AUTOSAR XML (schema 00046)
package /ComponentTypes
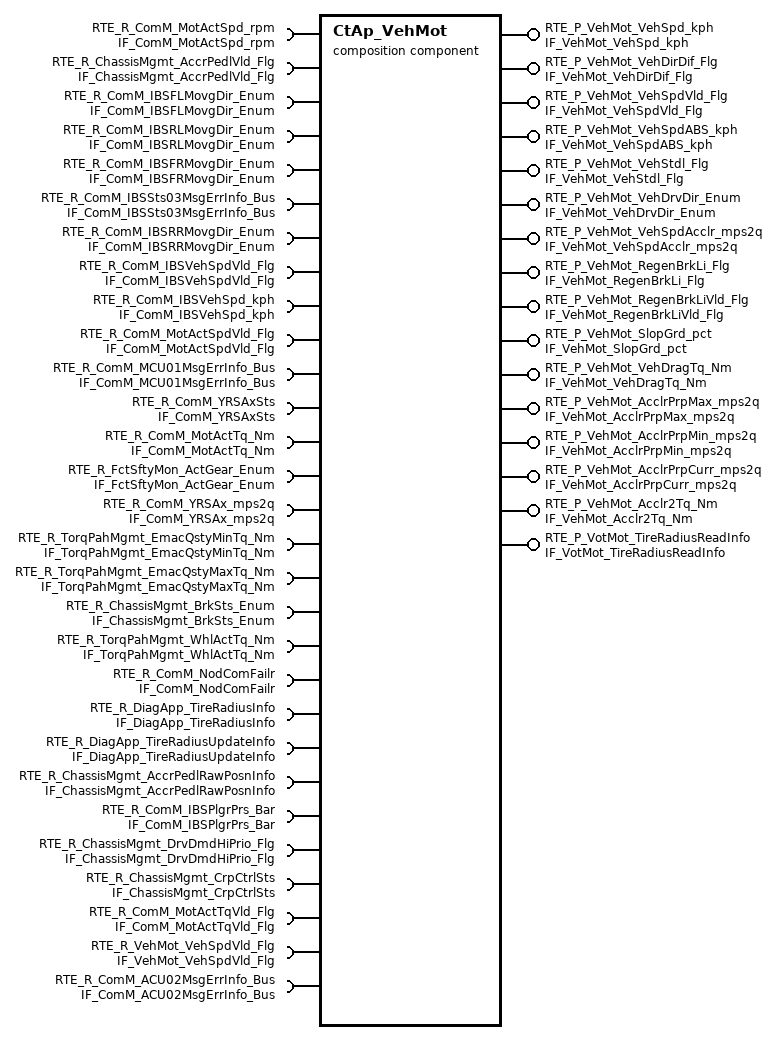
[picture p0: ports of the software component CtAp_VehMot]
  composition sw component type CtAp_VehMot
    require port RTE_R_ComM_MotActSpd_rpm: nonqueued-receiver-com-spec{data-element=tec_ComM_MotActSpd_rpm, filter=data-filter-type=ALWAYS, init-value=0}, required-interface=IF_ComM_MotActSpd_rpm
    15 x provide port:
      RTE_P_VehMot_VehSpd_kph: nonqueued-sender-com-spec{data-element=tec_VehMot_VehSpd_kph, init-value=0}, provided-interface=IF_VehMot_VehSpd_kph
      RTE_P_VehMot_VehDirDif_Flg: nonqueued-sender-com-spec{data-element=tec_VehMot_VehDirDif_Flg, init-value=0}, provided-interface=IF_VehMot_VehDirDif_Flg
      RTE_P_VehMot_VehSpdVld_Flg: nonqueued-sender-com-spec{data-element=tec_VehMot_VehSpdVld_Flg, init-value=0}, provided-interface=IF_VehMot_VehSpdVld_Flg
      RTE_P_VehMot_VehSpdABS_kph: nonqueued-sender-com-spec{data-element=tec_VehMot_VehSpdABS_kph, init-value=0}, provided-interface=IF_VehMot_VehSpdABS_kph
      RTE_P_VehMot_VehStdl_Flg: nonqueued-sender-com-spec{data-element=tec_VehMot_VehStdl_Flg, init-value=0}, provided-interface=IF_VehMot_VehStdl_Flg
      RTE_P_VehMot_VehDrvDir_Enum: nonqueued-sender-com-spec{data-element=tec_VehMot_VehDrvDir_Enum, init-value=0}, provided-interface=IF_VehMot_VehDrvDir_Enum
      RTE_P_VehMot_VehSpdAcclr_mps2q: nonqueued-sender-com-spec{data-element=tec_VehMot_VehSpdAcclr_mps2q, init-value=0}, provided-interface=IF_VehMot_VehSpdAcclr_mps2q
      RTE_P_VehMot_RegenBrkLi_Flg: nonqueued-sender-com-spec{data-element=tec_VehMot_RegenBrkLi_Flg, init-value=0}, provided-interface=IF_VehMot_RegenBrkLi_Flg
      RTE_P_VehMot_RegenBrkLiVld_Flg: nonqueued-sender-com-spec{data-element=tec_VehMot_RegenBrkLiVld_Flg, init-value=0}, provided-interface=IF_VehMot_RegenBrkLiVld_Flg
      RTE_P_VehMot_SlopGrd_pct: nonqueued-sender-com-spec{data-element=tec_VehMot_SlopGrd_pct, init-value=0}, provided-interface=IF_VehMot_SlopGrd_pct
      RTE_P_VehMot_VehDragTq_Nm: nonqueued-sender-com-spec{data-element=tec_VehMot_VehDragTq_Nm, init-value=0}, provided-interface=IF_VehMot_VehDragTq_Nm
      RTE_P_VehMot_AcclrPrpMax_mps2q: nonqueued-sender-com-spec{data-element=tec_VehMot_AcclrPrpMax_mps2q, init-value=0}, provided-interface=IF_VehMot_AcclrPrpMax_mps2q
      RTE_P_VehMot_AcclrPrpMin_mps2q: nonqueued-sender-com-spec{data-element=tec_VehMot_AcclrPrpMin_mps2q, init-value=0}, provided-interface=IF_VehMot_AcclrPrpMin_mps2q
      RTE_P_VehMot_AcclrPrpCurr_mps2q: nonqueued-sender-com-spec{data-element=tec_VehMot_AcclrPrpCurr_mps2q, init-value=0}, provided-interface=IF_VehMot_AcclrPrpCurr_mps2q
      RTE_P_VehMot_Acclr2Tq_Nm: nonqueued-sender-com-spec{data-element=tec_VehMot_Acclr2Tq_Nm, init-value=0}, provided-interface=IF_VehMot_Acclr2Tq_Nm
    19 x require port:
      RTE_R_ChassisMgmt_AccrPedlVld_Flg: nonqueued-receiver-com-spec{data-element=tec_ChassisMgmt_AccrPedlVld_Flg, filter=data-filter-type=ALWAYS, init-value=0}, required-interface=IF_ChassisMgmt_AccrPedlVld_Flg
      RTE_R_ComM_IBSFLMovgDir_Enum: nonqueued-receiver-com-spec{data-element=tec_ComM_IBSFLMovgDir_Enum, filter=data-filter-type=ALWAYS, init-value=0}, required-interface=IF_ComM_IBSFLMovgDir_Enum
      RTE_R_ComM_IBSRLMovgDir_Enum: nonqueued-receiver-com-spec{data-element=tec_ComM_IBSRLMovgDir_Enum, filter=data-filter-type=ALWAYS, init-value=0}, required-interface=IF_ComM_IBSRLMovgDir_Enum
      RTE_R_ComM_IBSFRMovgDir_Enum: nonqueued-receiver-com-spec{data-element=tec_ComM_IBSFRMovgDir_Enum, filter=data-filter-type=ALWAYS, init-value=0}, required-interface=IF_ComM_IBSFRMovgDir_Enum
      RTE_R_ComM_IBSSts03MsgErrInfo_Bus: required-interface=IF_ComM_IBSSts03MsgErrInfo_Bus
        required-com-specs:
          data-element=tec_ComM_IBSSts03CRCInfo_Bus, filter=data-filter-type=ALWAYS, init-value=fields=[ComM_MonStatIBSSts03CRCErrorInfo:0, ComM_MonResIBSSts03CRCErrorInfo:0, ComM_ErrStatIBSSts03CRCErrorInfo:0, ComM_ErrResIBSSts03CRCErrorInfo:0]
          data-element=tec_ComM_IBSSts03CRCDTCInfo_Bus, filter=data-filter-type=ALWAYS, init-value=fields=[ComM_MonStatIBSSts03CRCDTCErrorInfo:0, ComM_MonResIBSSts03CRCDTCErrorInfo:0, ComM_ErrStatIBSSts03CRCDTCErrorInfo:0, ComM_ErrResIBSSts03CRCDTCErrorInfo:0]
          data-element=tec_ComM_IBSSts03TimeoutDTCInfo_Bus, filter=data-filter-type=ALWAYS, init-value=fields=[ComM_MonStatIBSSts03TimeoutDTCErrorInfo:0, ComM_MonResIBSSts03TimeoutDTCErrorInfo:0, ComM_ErrStatIBSSts03TimeoutDTCErrorInfo:0, ComM_ErrResIBSSts03TimeoutDTCErrorInfo:0]
          data-element=tec_ComM_IBSSts03E2ETimeoutInfo_Bus, filter=data-filter-type=ALWAYS, init-value=fields=[ComM_MonStatIBSSts03E2ETimeoutInfo:0, ComM_MonResIBSSts03E2ETimeoutInfo:0, ComM_ErrStatIBSSts03E2ETimeoutInfo:0, ComM_ErrResIBSSts03E2ETimeoutInfo:0]
      RTE_R_ComM_IBSRRMovgDir_Enum: nonqueued-receiver-com-spec{data-element=tec_ComM_IBSRRMovgDir_Enum, filter=data-filter-type=ALWAYS, init-value=0}, required-interface=IF_ComM_IBSRRMovgDir_Enum
      RTE_R_ComM_IBSVehSpdVld_Flg: nonqueued-receiver-com-spec{data-element=tec_ComM_IBSVehSpdVld_Flg, filter=data-filter-type=ALWAYS, init-value=0}, required-interface=IF_ComM_IBSVehSpdVld_Flg
      RTE_R_ComM_IBSVehSpd_kph: nonqueued-receiver-com-spec{data-element=tec_ComM_IBSVehSpd_kph, filter=data-filter-type=ALWAYS, init-value=0}, required-interface=IF_ComM_IBSVehSpd_kph
      RTE_R_ComM_MotActSpdVld_Flg: nonqueued-receiver-com-spec{data-element=tec_ComM_MotActSpdVld_Flg, filter=data-filter-type=ALWAYS, init-value=0}, required-interface=IF_ComM_MotActSpdVld_Flg
      RTE_R_ComM_MCU01MsgErrInfo_Bus: required-interface=IF_ComM_MCU01MsgErrInfo_Bus
        required-com-specs:
          data-element=tec_ComM_MCU01TimeoutInfo_Bus, filter=data-filter-type=ALWAYS, init-value=fields=[ComM_MonStatMCU01TimeoutInfo:0, ComM_MonResMCU01TimeoutInfo:0, ComM_ErrStatMCU01TimeoutInfo:0, ComM_ErrResMCU01TimeoutInfo:0]
          data-element=tec_ComM_MCU01CRCDTCInfo_Bus, filter=data-filter-type=ALWAYS, init-value=fields=[ComM_MonStatMCU01CRCDTCErrorInfo:0, ComM_MonResMCU01CRCDTCErrorInfo:0, ComM_ErrStatMCU01CRCDTCErrorInfo:0, ComM_ErrResMCU01CRCDTCErrorInfo:0]
          data-element=tec_ComM_MCU01CRCInfo_Bus, filter=data-filter-type=ALWAYS, init-value=fields=[ComM_MonStatMCU01CRCErrorInfo:0, ComM_MonResMCU01CRCErrorInfo:0, ComM_ErrStatMCU01CRCErrorInfo:0, ComM_ErrResMCU01CRCErrorInfo:0]
          data-element=tec_ComM_MCU01TimeoutDTCInfo_Bus, filter=data-filter-type=ALWAYS, init-value=fields=[ComM_MonStatMCU01TimeoutDTCErrorInfo:0, ComM_MonResMCU01TimeoutDTCErrorInfo:0, ComM_ErrStatMCU01TimeoutDTCErrorInfo:0, ComM_ErrResMCU01TimeoutDTCErrorInfo:0]
          data-element=tec_ComM_MCU01E2ETimeoutInfo_Bus, filter=data-filter-type=ALWAYS, init-value=fields=[ComM_MonStatMCU01E2ETimeoutInfo:0, ComM_MonResMCU01E2ETimeoutInfo:0, ComM_ErrStatMCU01E2ETimeoutInfo:0, ComM_ErrResMCU01E2ETimeoutInfo:0]
      RTE_R_ComM_YRSAxSts: nonqueued-receiver-com-spec{data-element=tec_ComM_YRSAxSts, filter=data-filter-type=ALWAYS}, required-interface=IF_ComM_YRSAxSts
      RTE_R_ComM_MotActTq_Nm: nonqueued-receiver-com-spec{data-element=tec_ComM_MotActTq_Nm, filter=data-filter-type=ALWAYS, init-value=0}, required-interface=IF_ComM_MotActTq_Nm
      RTE_R_FctSftyMon_ActGear_Enum: nonqueued-receiver-com-spec{data-element=tec_FctSftyMon_ActGear_Enum, filter=data-filter-type=ALWAYS, init-value=0}, required-interface=IF_FctSftyMon_ActGear_Enum
      RTE_R_ComM_YRSAx_mps2q: nonqueued-receiver-com-spec{data-element=tec_ComM_YRSAx_mps2q, filter=data-filter-type=ALWAYS, init-value=0}, required-interface=IF_ComM_YRSAx_mps2q
      RTE_R_TorqPahMgmt_EmacQstyMinTq_Nm: nonqueued-receiver-com-spec{data-element=tec_TorqPahMgmt_EmacQstyMinTq_Nm, filter=data-filter-type=ALWAYS, init-value=0}, required-interface=IF_TorqPahMgmt_EmacQstyMinTq_Nm
      RTE_R_TorqPahMgmt_EmacQstyMaxTq_Nm: nonqueued-receiver-com-spec{data-element=tec_TorqPahMgmt_EmacQstyMaxTq_Nm, filter=data-filter-type=ALWAYS, init-value=0}, required-interface=IF_TorqPahMgmt_EmacQstyMaxTq_Nm
      RTE_R_ChassisMgmt_BrkSts_Enum: nonqueued-receiver-com-spec{data-element=tec_ChassisMgmt_BrkSts_Enum, filter=data-filter-type=ALWAYS, init-value=0}, required-interface=IF_ChassisMgmt_BrkSts_Enum
      RTE_R_TorqPahMgmt_WhlActTq_Nm: nonqueued-receiver-com-spec{data-element=tec_TorqPahMgmt_WhlActTq_Nm, filter=data-filter-type=ALWAYS, init-value=0}, required-interface=IF_TorqPahMgmt_WhlActTq_Nm
      RTE_R_ComM_NodComFailr: required-interface=IF_ComM_NodComFailr
        required-com-specs:
          data-element=tec_ComM_ACUNodComFailr_Flg, filter=data-filter-type=ALWAYS, init-value=0
          data-element=tec_ComM_SGWNodComFailr_Flg, filter=data-filter-type=ALWAYS, init-value=0
          data-element=tec_ComM_CGWNodComFailr_Flg, filter=data-filter-type=ALWAYS, init-value=0
          data-element=tec_ComM_TCUNodComFailr_Flg, filter=data-filter-type=ALWAYS, init-value=0
          data-element=tec_ComM_BCMNodComFailr_Flg, filter=data-filter-type=ALWAYS, init-value=0
          data-element=tec_ComM_PRNDNodComFailr_Flg, filter=data-filter-type=ALWAYS, init-value=0
          data-element=tec_ComM_IVINodComFailr_Flg, filter=data-filter-type=ALWAYS, init-value=0
          data-element=tec_ComM_DCDCNodComFailr_Flg, filter=data-filter-type=ALWAYS, init-value=0
          data-element=tec_ComM_OBCNodComFailr_Flg, filter=data-filter-type=ALWAYS, init-value=0
          data-element=tec_ComM_CHIBSNodComFailr_Flg, filter=data-filter-type=ALWAYS, init-value=0
          data-element=tec_ComM_MCUNodComFailr_Flg, filter=data-filter-type=ALWAYS, init-value=0
          data-element=tec_ComM_EVCOMNodComFailr_Flg, filter=data-filter-type=ALWAYS, init-value=0
          data-element=tec_ComM_EPTIBSNodComFailr_Flg, filter=data-filter-type=ALWAYS, init-value=0
          data-element=tec_ComM_DCMNodComFailr_Flg, filter=data-filter-type=ALWAYS, init-value=0
          data-element=tec_ComM_BMSNodComFailr_Flg, filter=data-filter-type=ALWAYS, init-value=0
          data-element=tec_ComM_APTCNodComFailr_Flg, filter=data-filter-type=ALWAYS, init-value=0
          data-element=tec_ComM_ADCUNodComFailr_Flg, filter=data-filter-type=ALWAYS, init-value=0
          data-element=tec_ComM_DCMRRNodComFailr_Flg, filter=data-filter-type=ALWAYS, init-value=0
          data-element=tec_ComM_DCMRLNodComFailr_Flg, filter=data-filter-type=ALWAYS, init-value=0
          data-element=tec_ComM_DCMFRNodComFailr_Flg, filter=data-filter-type=ALWAYS, init-value=0
          data-element=tec_ComM_DCMFLNodComFailr_Flg, filter=data-filter-type=ALWAYS, init-value=0
          data-element=tec_ComM_SGWCHNodComFailr_Flg, filter=data-filter-type=ALWAYS, init-value=0
    provide port RTE_P_VotMot_TireRadiusReadInfo: nonqueued-sender-com-spec{data-element=tec_VotMot_TireRadiusReadInfo, init-value=0}, provided-interface=IF_VotMot_TireRadiusReadInfo
    9 x require port:
      RTE_R_DiagApp_TireRadiusInfo: nonqueued-receiver-com-spec{data-element=tec_DiagApp_TireRadiusInfo, filter=data-filter-type=ALWAYS, init-value=0}, required-interface=IF_DiagApp_TireRadiusInfo
      RTE_R_DiagApp_TireRadiusUpdateInfo: nonqueued-receiver-com-spec{data-element=tec_DiagApp_TireRadiusUpdateInfo, filter=data-filter-type=ALWAYS, init-value=0}, required-interface=IF_DiagApp_TireRadiusUpdateInfo
      RTE_R_ChassisMgmt_AccrPedlRawPosnInfo: nonqueued-receiver-com-spec{data-element=tec_ChassisMgmt_AccrPedlRawPosnInfo, filter=data-filter-type=ALWAYS, init-value=0}, required-interface=IF_ChassisMgmt_AccrPedlRawPosnInfo
      RTE_R_ComM_IBSPlgrPrs_Bar: nonqueued-receiver-com-spec{data-element=tec_ComM_IBSPlgrPrs_Bar, filter=data-filter-type=ALWAYS, init-value=0}, required-interface=IF_ComM_IBSPlgrPrs_Bar
      RTE_R_ChassisMgmt_DrvDmdHiPrio_Flg: nonqueued-receiver-com-spec{data-element=tec_ChassisMgmt_DrvDmdHiPrio_Flg, filter=data-filter-type=ALWAYS, init-value=0}, required-interface=IF_ChassisMgmt_DrvDmdHiPrio_Flg
      RTE_R_ChassisMgmt_CrpCtrlSts: nonqueued-receiver-com-spec{data-element=tec_ChassisMgmt_CrpCtrlSts, filter=data-filter-type=ALWAYS, init-value=0}, required-interface=IF_ChassisMgmt_CrpCtrlSts
      RTE_R_ComM_MotActTqVld_Flg: nonqueued-receiver-com-spec{data-element=tec_ComM_MotActTqVld_Flg, filter=data-filter-type=ALWAYS, init-value=0}, required-interface=IF_ComM_MotActTqVld_Flg
      RTE_R_VehMot_VehSpdVld_Flg: nonqueued-receiver-com-spec{data-element=tec_VehMot_VehSpdVld_Flg, filter=data-filter-type=ALWAYS, init-value=0}, required-interface=IF_VehMot_VehSpdVld_Flg
      RTE_R_ComM_ACU02MsgErrInfo_Bus: required-interface=IF_ComM_ACU02MsgErrInfo_Bus
        required-com-specs:
          data-element=tec_ComM_ACU02CRCDTCInfo_Bus, filter=data-filter-type=ALWAYS, init-value=fields=[ComM_MonStatACU02CRCDTCErrorInfo:0, ComM_MonResACU02CRCDTCErrorInfo:0, ComM_ErrStatACU02CRCDTCErrorInfo:0, ComM_ErrResACU02CRCDTCErrorInfo:0]
          data-element=tec_ComM_ACU02TimeoutDTCInfo_Bus, filter=data-filter-type=ALWAYS, init-value=fields=[ComM_MonStatACU02TimeoutDTCInfo:0, ComM_MonResACU02TimeoutDTCInfo:0, ComM_ErrStatACU02TimeoutDTCInfo:0, ComM_ErrResACU02TimeoutDTCInfo:0]
          data-element=tec_ComM_ACU02TimeoutInfo_Bus, filter=data-filter-type=ALWAYS, init-value=fields=[ComM_MonStatACU02TimeoutInfo:0, ComM_MonResACU02TimeoutInfo:0, ComM_ErrStatACU02TimeoutInfo:0, ComM_ErrResACU02TimeoutInfo:0]
    4 x component:
      CtAp_VehSpd: type=CtAp_VehSpd
      CtAp_AccCal: type=CtAp_AccCal
      CtAp_SlopEst: type=CtAp_SlopEst
      CtAp_ResEst: type=CtAp_ResEst
    delegate CtAp_ResEst.RTE_R_TorqPahMgmt_EmacQstyMaxTq_Nm <-> outer port RTE_R_TorqPahMgmt_EmacQstyMaxTq_Nm
    delegate CtAp_SlopEst.RTE_R_ChassisMgmt_AccrPedlVld_Flg <-> outer port RTE_R_ChassisMgmt_AccrPedlVld_Flg
    delegate CtAp_ResEst.RTE_R_ComM_MotActTq_Nm <-> outer port RTE_R_ComM_MotActTq_Nm
    delegate CtAp_ResEst.RTE_R_ComM_YRSAx_mps2q <-> outer port RTE_R_ComM_YRSAx_mps2q
    delegate CtAp_ResEst.RTE_R_TorqPahMgmt_EmacQstyMinTq_Nm <-> outer port RTE_R_TorqPahMgmt_EmacQstyMinTq_Nm
    delegate CtAp_VehSpd.RTE_R_ComM_MotActSpd_rpm <-> outer port RTE_R_ComM_MotActSpd_rpm
    delegate CtAp_VehSpd.RTE_P_VehMot_VehStdl_Flg <-> outer port RTE_P_VehMot_VehStdl_Flg
    delegate CtAp_VehSpd.RTE_R_ComM_IBSFLMovgDir_Enum <-> outer port RTE_R_ComM_IBSFLMovgDir_Enum
    delegate CtAp_AccCal.RTE_P_VehMot_VehSpdAcclr_mps2q <-> outer port RTE_P_VehMot_VehSpdAcclr_mps2q
    delegate CtAp_VehSpd.RTE_R_ComM_IBSVehSpd_kph <-> outer port RTE_R_ComM_IBSVehSpd_kph
    delegate CtAp_VehSpd.RTE_R_ComM_IBSRRMovgDir_Enum <-> outer port RTE_R_ComM_IBSRRMovgDir_Enum
    delegate CtAp_ResEst.RTE_P_VehMot_Acclr2Tq_Nm <-> outer port RTE_P_VehMot_Acclr2Tq_Nm
    delegate CtAp_ResEst.RTE_P_VehMot_VehDragTq_Nm <-> outer port RTE_P_VehMot_VehDragTq_Nm
    delegate CtAp_ResEst.RTE_P_VehMot_AcclrPrpCurr_mps2q <-> outer port RTE_P_VehMot_AcclrPrpCurr_mps2q
    delegate CtAp_VehSpd.RTE_R_ComM_MotActSpdVld_Flg <-> outer port RTE_R_ComM_MotActSpdVld_Flg
    delegate CtAp_VehSpd.RTE_R_FctSftyMon_ActGear_Enum <-> outer port RTE_R_FctSftyMon_ActGear_Enum
    delegate CtAp_VehSpd.RTE_P_VehMot_VehDirDif_Flg <-> outer port RTE_P_VehMot_VehDirDif_Flg
    delegate CtAp_SlopEst.RTE_P_VehMot_SlopGrd_pct <-> outer port RTE_P_VehMot_SlopGrd_pct
    delegate CtAp_VehSpd.RTE_R_ComM_IBSFRMovgDir_Enum <-> outer port RTE_R_ComM_IBSFRMovgDir_Enum
    delegate CtAp_AccCal.RTE_P_VehMot_RegenBrkLi_Flg <-> outer port RTE_P_VehMot_RegenBrkLi_Flg
    delegate CtAp_VehSpd.RTE_P_VehMot_VehSpdVld_Flg <-> outer port RTE_P_VehMot_VehSpdVld_Flg
    delegate CtAp_VehSpd.RTE_R_ComM_IBSVehSpdVld_Flg <-> outer port RTE_R_ComM_IBSVehSpdVld_Flg
    delegate CtAp_VehSpd.RTE_R_ComM_IBSRLMovgDir_Enum <-> outer port RTE_R_ComM_IBSRLMovgDir_Enum
    delegate CtAp_VehSpd.RTE_P_VehMot_VehDrvDir_Enum <-> outer port RTE_P_VehMot_VehDrvDir_Enum
    delegate CtAp_VehSpd.RTE_R_ComM_IBSSts03MsgErrInfo_Bus <-> outer port RTE_R_ComM_IBSSts03MsgErrInfo_Bus
    delegate CtAp_VehSpd.RTE_R_ComM_MCU01MsgErrInfo_Bus <-> outer port RTE_R_ComM_MCU01MsgErrInfo_Bus
    delegate CtAp_VehSpd.RTE_P_VehMot_VehSpd_kph <-> outer port RTE_P_VehMot_VehSpd_kph
    delegate CtAp_ResEst.RTE_P_VehMot_AcclrPrpMax_mps2q <-> outer port RTE_P_VehMot_AcclrPrpMax_mps2q
    delegate CtAp_ResEst.RTE_P_VehMot_AcclrPrpMin_mps2q <-> outer port RTE_P_VehMot_AcclrPrpMin_mps2q
    delegate CtAp_VehSpd.RTE_P_VehMot_VehSpdABS_kph <-> outer port RTE_P_VehMot_VehSpdABS_kph
    connect CtAp_VehSpd.RTE_P_VehMot_VehSpd_kph -> CtAp_AccCal.RTE_R_VehMot_VehSpd_kph
    delegate CtAp_AccCal.RTE_R_ComM_YRSAx_mps2q <-> outer port RTE_R_ComM_YRSAx_mps2q
    delegate CtAp_SlopEst.RTE_R_ComM_YRSAxSts <-> outer port RTE_R_ComM_YRSAxSts
    delegate CtAp_SlopEst.RTE_R_ComM_YRSAx_mps2q <-> outer port RTE_R_ComM_YRSAx_mps2q
    connect CtAp_AccCal.RTE_P_VehMot_VehSpdAcclr_mps2q -> CtAp_SlopEst.RTE_R_VehMot_VehSpdAcclr_mps2q
    connect CtAp_VehSpd.RTE_P_VehMot_VehSpd_kph -> CtAp_SlopEst.RTE_R_VehMot_VehSpd_kph
    delegate CtAp_AccCal.RTE_P_VehMot_RegenBrkLiVld_Flg <-> outer port RTE_P_VehMot_RegenBrkLiVld_Flg
    connect CtAp_VehSpd.RTE_P_VehMot_VehSpdVld_Flg -> CtAp_ResEst.RTE_R_VehMot_VehSpdVld_Flg
    connect CtAp_VehSpd.RTE_P_VehMot_VehSpd_kph -> CtAp_ResEst.RTE_R_VehMot_VehSpd_kph
    delegate CtAp_ResEst.RTE_R_ComM_YRSAxSts <-> outer port RTE_R_ComM_YRSAxSts
    connect CtAp_AccCal.RTE_P_VehMot_VehSpdAcclr_mps2q -> CtAp_ResEst.RTE_R_VehMot_VehSpdAcclr_mps2q
    delegate CtAp_SlopEst.RTE_R_ChassisMgmt_BrkSts_Enum <-> outer port RTE_R_ChassisMgmt_BrkSts_Enum
    delegate CtAp_ResEst.RTE_R_ChassisMgmt_BrkSts_Enum <-> outer port RTE_R_ChassisMgmt_BrkSts_Enum
    delegate CtAp_AccCal.RTE_R_FctSftyMon_ActGear_Enum <-> outer port RTE_R_FctSftyMon_ActGear_Enum
    connect CtAp_VehSpd.RTE_P_VehMot_VehSpdABS_kph -> CtAp_ResEst.RTE_R_VehMot_VehSpdABS_kph
    delegate CtAp_ResEst.RTE_R_TorqPahMgmt_WhlActTq_Nm <-> outer port RTE_R_TorqPahMgmt_WhlActTq_Nm
    connect CtAp_VehSpd.RTE_P_VehMot_VehSpdVld_Flg -> CtAp_AccCal.RTE_R_VehMot_VehSpdVld_Flg
    delegate CtAp_VehSpd.RTE_R_ComM_NodComFailr <-> outer port RTE_R_ComM_NodComFailr
    delegate CtAp_VehSpd.RTE_P_VotMot_TireRadiusReadInfo <-> outer port RTE_P_VotMot_TireRadiusReadInfo
    delegate CtAp_VehSpd.RTE_R_DiagApp_TireRadiusInfo <-> outer port RTE_R_DiagApp_TireRadiusInfo
    delegate CtAp_VehSpd.RTE_R_DiagApp_TireRadiusUpdateInfo <-> outer port RTE_R_DiagApp_TireRadiusUpdateInfo
    delegate CtAp_SlopEst.RTE_R_ChassisMgmt_AccrPedlRawPosnInfo <-> outer port RTE_R_ChassisMgmt_AccrPedlRawPosnInfo
    delegate CtAp_SlopEst.RTE_R_ComM_IBSPlgrPrs_Bar <-> outer port RTE_R_ComM_IBSPlgrPrs_Bar
    delegate CtAp_SlopEst.RTE_R_ChassisMgmt_DrvDmdHiPrio_Flg <-> outer port RTE_R_ChassisMgmt_DrvDmdHiPrio_Flg
    delegate CtAp_SlopEst.RTE_R_ChassisMgmt_CrpCtrlSts <-> outer port RTE_R_ChassisMgmt_CrpCtrlSts
    delegate CtAp_SlopEst.RTE_R_ComM_MotActTqVld_Flg <-> outer port RTE_R_ComM_MotActTqVld_Flg
    delegate CtAp_SlopEst.RTE_R_VehMot_VehSpdVld_Flg <-> outer port RTE_R_VehMot_VehSpdVld_Flg
    delegate CtAp_SlopEst.RTE_R_ComM_MotActTq_Nm <-> outer port RTE_R_ComM_MotActTq_Nm
    delegate CtAp_SlopEst.RTE_R_TorqPahMgmt_WhlActTq_Nm <-> outer port RTE_R_TorqPahMgmt_WhlActTq_Nm
    delegate CtAp_SlopEst.RTE_R_FctSftyMon_ActGear_Enum <-> outer port RTE_R_FctSftyMon_ActGear_Enum
    connect CtAp_VehSpd.RTE_P_VehMot_VehTirRdInfo -> CtAp_ResEst.RTE_R_VehMot_VehTirRdInfo
    delegate CtAp_AccCal.RTE_R_ComM_YRSAxSts <-> outer port RTE_R_ComM_YRSAxSts
    delegate CtAp_SlopEst.RTE_R_ComM_ACU02MsgErrInfo_Bus <-> outer port RTE_R_ComM_ACU02MsgErrInfo_Bus
